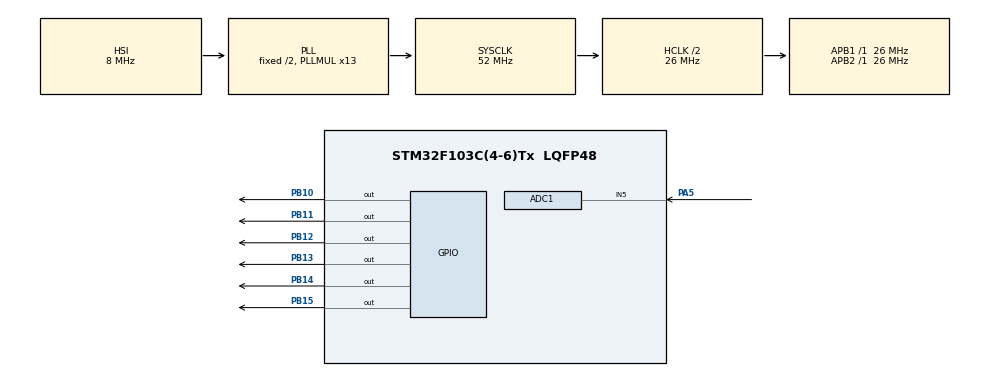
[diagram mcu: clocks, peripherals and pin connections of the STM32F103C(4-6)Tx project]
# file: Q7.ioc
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ADC1.Channel-0\#ChannelRegularConversion=ADC_CHANNEL_5
ADC1.NbrOfConversionFlag=1
ADC1.Rank-0\#ChannelRegularConversion=1
ADC1.SamplingTime-0\#ChannelRegularConversion=ADC_SAMPLETIME_1CYCLE_5
ADC1.master=1
Mcu.Family=STM32F1
Mcu.Name=STM32F103C(4-6)Tx
Mcu.Package=LQFP48
NVIC.PriorityGroup=NVIC_PRIORITYGROUP_4
PA5.Signal=ADCx_IN5
PB10.Signal=GPIO_Output
PB11.Signal=GPIO_Output
PB12.Signal=GPIO_Output
PB13.Signal=GPIO_Output
PB14.Signal=GPIO_Output
PB15.Signal=GPIO_Output
ProjectManager.HeapSize=0x200
ProjectManager.StackSize=0x400
ProjectManager.TargetToolchain=STM32CubeIDE
RCC.AHBCLKDivider=RCC_SYSCLK_DIV2
RCC.AHBFreq_Value=26000000
RCC.APB1Freq_Value=26000000
RCC.APB1TimFreq_Value=26000000
RCC.APB2Freq_Value=26000000
RCC.APB2TimFreq_Value=26000000
RCC.HCLKFreq_Value=26000000
RCC.PLLMUL=RCC_PLL_MUL13
RCC.SYSCLKFreq_VALUE=52000000
RCC.SYSCLKSource=RCC_SYSCLKSOURCE_PLLCLK
RCC.USBFreq_Value=52000000
SH.ADCx_IN5.0=ADC1_IN5,IN5
VP_SYS_VS_ND.Mode=No_Debug
board=custom

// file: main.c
/* USER CODE BEGIN Header */
/**
  ******************************************************************************
  * @file           : main.c
  * @brief          : Main program body
  ******************************************************************************
  * @attention
  *
  * Copyright (c) 2023 STMicroelectronics.
  * All rights reserved.
  *
  * This software is licensed under terms that can be found in the LICENSE file
  * in the root directory of this software component.
  * If no LICENSE file comes with this software, it is provided AS-IS.
  *
  ******************************************************************************
  */
/* USER CODE END Header */
#include "main.h"

/* USER CODE BEGIN Includes */
#include "lcd_txt.h"
/* USER CODE END Includes */

ADC_HandleTypeDef hadc1;

void SystemClock_Config(void);
static void MX_GPIO_Init(void);
static void MX_ADC1_Init(void);

int main(void)
{
  /* USER CODE BEGIN 1 */
	int analogValue, voltageout, tempA, tempB, remainder, quotient, temp;
  /* USER CODE END 1 */

  /* MCU Configuration--------------------------------------------------------*/

  /* Reset of all peripherals, Initializes the Flash interface and the Systick. */
  HAL_Init();

  /* Configure the system clock */
  SystemClock_Config();

  /* Initialize all configured peripherals */
  MX_GPIO_Init();
  MX_ADC1_Init();
  /* USER CODE BEGIN 2 */
  lcd_init();
  lcd_clear();
  /* USER CODE END 2 */

  /* Infinite loop */
  /* USER CODE BEGIN WHILE */
  while (1)
  {   ADC1->CR2 |=0x00400000;
  	  while(!( ADC1->SR & 2)) {}
  	  analogValue = ADC1->DR;
  	  voltageout = (analogValue * 5000)/4096;
  	  temp = voltageout/10;

  	  quotient = temp/10;
  	  remainder = temp%10;
  	  tempA = quotient + 0x30;
  	  tempB = remainder + 0x30;

    /* USER CODE END WHILE */

  }
}

void SystemClock_Config(void)
{
  RCC_OscInitTypeDef RCC_OscInitStruct = {0};
  RCC_ClkInitTypeDef RCC_ClkInitStruct = {0};
  RCC_PeriphCLKInitTypeDef PeriphClkInit = {0};

  /** Initializes the RCC Oscillators according to the specified parameters
  * in the RCC_OscInitTypeDef structure.
  */
  RCC_OscInitStruct.OscillatorType = RCC_OSCILLATORTYPE_HSI;
  RCC_OscInitStruct.HSIState = RCC_HSI_ON;
  RCC_OscInitStruct.HSICalibrationValue = RCC_HSICALIBRATION_DEFAULT;
  RCC_OscInitStruct.PLL.PLLState = RCC_PLL_ON;
  RCC_OscInitStruct.PLL.PLLSource = RCC_PLLSOURCE_HSI_DIV2;
  RCC_OscInitStruct.PLL.PLLMUL = RCC_PLL_MUL13;
  if (HAL_RCC_OscConfig(&RCC_OscInitStruct) != HAL_OK)
  {
    Error_Handler();
  }

  /** Initializes the CPU, AHB and APB buses clocks
  */
  RCC_ClkInitStruct.ClockType = RCC_CLOCKTYPE_HCLK|RCC_CLOCKTYPE_SYSCLK
                              |RCC_CLOCKTYPE_PCLK1|RCC_CLOCKTYPE_PCLK2;
  RCC_ClkInitStruct.SYSCLKSource = RCC_SYSCLKSOURCE_PLLCLK;
  RCC_ClkInitStruct.AHBCLKDivider = RCC_SYSCLK_DIV2;
  RCC_ClkInitStruct.APB1CLKDivider = RCC_HCLK_DIV1;
  RCC_ClkInitStruct.APB2CLKDivider = RCC_HCLK_DIV1;

  if (HAL_RCC_ClockConfig(&RCC_ClkInitStruct, FLASH_LATENCY_2) != HAL_OK)
  {
    Error_Handler();
  }
  PeriphClkInit.PeriphClockSelection = RCC_PERIPHCLK_ADC;
  PeriphClkInit.AdcClockSelection = RCC_ADCPCLK2_DIV2;
  if (HAL_RCCEx_PeriphCLKConfig(&PeriphClkInit) != HAL_OK)
  {
    Error_Handler();
  }
}

static void MX_ADC1_Init(void)
{

  ADC_ChannelConfTypeDef sConfig = {0};

  /** Common config
  */
  hadc1.Instance = ADC1;
  hadc1.Init.ScanConvMode = ADC_SCAN_DISABLE;
  hadc1.Init.ContinuousConvMode = DISABLE;
  hadc1.Init.DiscontinuousConvMode = DISABLE;
  hadc1.Init.ExternalTrigConv = ADC_SOFTWARE_START;
  hadc1.Init.DataAlign = ADC_DATAALIGN_RIGHT;
  hadc1.Init.NbrOfConversion = 1;
  if (HAL_ADC_Init(&hadc1) != HAL_OK)
  {
    Error_Handler();
  }

  /** Configure Regular Channel
  */
  sConfig.Channel = ADC_CHANNEL_5;
  sConfig.Rank = ADC_REGULAR_RANK_1;
  sConfig.SamplingTime = ADC_SAMPLETIME_1CYCLE_5;
  if (HAL_ADC_ConfigChannel(&hadc1, &sConfig) != HAL_OK)
  {
    Error_Handler();
  }

}

static void MX_GPIO_Init(void)
{
  GPIO_InitTypeDef GPIO_InitStruct = {0};

  /* GPIO Ports Clock Enable */
  __HAL_RCC_GPIOA_CLK_ENABLE();
  __HAL_RCC_GPIOB_CLK_ENABLE();

  /*Configure GPIO pin Output Level */
  HAL_GPIO_WritePin(GPIOB, GPIO_PIN_10|GPIO_PIN_11|GPIO_PIN_12|GPIO_PIN_13
                          |GPIO_PIN_14|GPIO_PIN_15, GPIO_PIN_RESET);

  /*Configure GPIO pins : PB10 PB11 PB12 PB13
                           PB14 PB15 */
  GPIO_InitStruct.Pin = GPIO_PIN_10|GPIO_PIN_11|GPIO_PIN_12|GPIO_PIN_13
                          |GPIO_PIN_14|GPIO_PIN_15;
  GPIO_InitStruct.Mode = GPIO_MODE_OUTPUT_PP;
  GPIO_InitStruct.Pull = GPIO_NOPULL;
  GPIO_InitStruct.Speed = GPIO_SPEED_FREQ_LOW;
  HAL_GPIO_Init(GPIOB, &GPIO_InitStruct);

}

void Error_Handler(void)
{
  __disable_irq();
  while (1)
  {
  }
}
